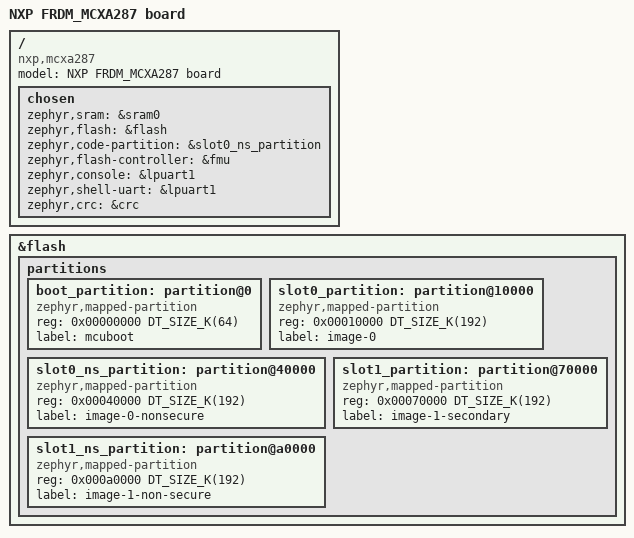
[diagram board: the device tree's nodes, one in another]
/*
 * SPDX-FileCopyrightText: Copyright 2026 NXP
 *
 * SPDX-License-Identifier: Apache-2.0
 */

/dts-v1/;

#include <nxp/mcx/mcxa/nxp_mcxa287_ns.dtsi>
#include "frdm_mcxa287.dtsi"

/ {
	compatible = "nxp,mcxa287", "nxp,mcx";
	model = "NXP FRDM_MCXA287 board";

	chosen {
		zephyr,sram = &sram0;
		zephyr,flash = &flash;
		zephyr,code-partition = &slot0_ns_partition;
		zephyr,flash-controller = &fmu;
		zephyr,console = &lpuart1;
		zephyr,shell-uart = &lpuart1;
		zephyr,crc = &crc;
	};
};

&flash {
	/delete-node/ partitions;

	partitions {
		ranges;
		#address-cells = <1>;
		#size-cells = <1>;

		boot_partition: partition@0 {
			compatible = "zephyr,mapped-partition";
			reg = <0x00000000 DT_SIZE_K(64)>;  /* 64 KB: 0x0000_0000 - 0x0000_FFFF */
			label = "mcuboot";
		};

		/* Secure image - primary */
		slot0_partition: partition@10000 {
			compatible = "zephyr,mapped-partition";
			reg = <0x00010000 DT_SIZE_K(192)>; /* 192 KB: 0x0001_0000 - 0x0003_FFFF */
			label = "image-0";
		};

		/* Non-secure image - primary */
		slot0_ns_partition: partition@40000 {
			compatible = "zephyr,mapped-partition";
			reg = <0x00040000 DT_SIZE_K(192)>; /* 192 KB: 0x0004_0000 - 0x0006_FFFF */
			label = "image-0-nonsecure";
		};

		/* Secure image - secondary */
		slot1_partition: partition@70000 {
			compatible = "zephyr,mapped-partition";
			reg = <0x00070000 DT_SIZE_K(192)>; /* 192 KB: 0x0007_0000 - 0x0009_FFFF */
			label = "image-1-secondary";
		};

		/* Non-secure image - secondary */
		slot1_ns_partition: partition@a0000 {
			compatible = "zephyr,mapped-partition";
			reg = <0x000a0000 DT_SIZE_K(192)>; /* 192 KB: 0x000A_0000 - 0x000C_FFFF */
			label = "image-1-non-secure";
		};

		/*
		 * All partition sizes must be aligned to the flash memory sector size (8 KB).
		 *
		 * BL2 / MCUBoot
		 */
	};
};
